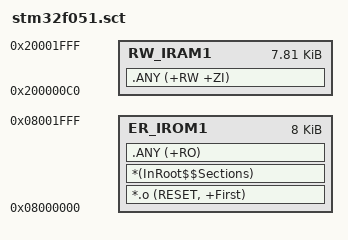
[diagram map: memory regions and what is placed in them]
; *************************************************************
; *** Scatter-Loading Description File generated by uVision ***
; *************************************************************
; Set bootloader size to max 8kb.
LR_IROM1 0x08000000 0x00002000  {    ; load region size_region
  ER_IROM1 0x08000000 0x00002000  {  ; load address = execution address
   *.o (RESET, +First)
   *(InRoot$$Sections)
   .ANY (+RO)
  }
  RW_IRAM1 0x200000C0 0x00001F40  {  ; RW data - first 192 bytes reserved by OpenBLT
   .ANY (+RW +ZI)
  }
}

